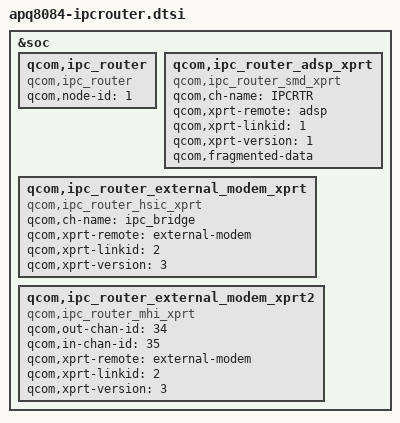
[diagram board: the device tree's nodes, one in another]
/* Copyright (c) 2014-2015, The Linux Foundation. All rights reserved.
 *
 * This program is free software; you can redistribute it and/or modify
 * it under the terms of the GNU General Public License version 2 and
 * only version 2 as published by the Free Software Foundation.
 *
 * This program is distributed in the hope that it will be useful,
 * but WITHOUT ANY WARRANTY; without even the implied warranty of
 * MERCHANTABILITY or FITNESS FOR A PARTICULAR PURPOSE.  See the
 * GNU General Public License for more details.
 */

&soc {
	qcom,ipc_router {
		compatible = "qcom,ipc_router";
		qcom,node-id = <1>;
	};

	qcom,ipc_router_adsp_xprt {
		compatible = "qcom,ipc_router_smd_xprt";
		qcom,ch-name = "IPCRTR";
		qcom,xprt-remote = "adsp";
		qcom,xprt-linkid = <1>;
		qcom,xprt-version = <1>;
		qcom,fragmented-data;
	};

	qcom,ipc_router_external_modem_xprt {
		compatible = "qcom,ipc_router_hsic_xprt";
	        qcom,ch-name = "ipc_bridge";
		qcom,xprt-remote = "external-modem";
		qcom,xprt-linkid = <2>;
		qcom,xprt-version = <3>;
	};

	qcom,ipc_router_external_modem_xprt2 {
		compatible = "qcom,ipc_router_mhi_xprt";
		qcom,out-chan-id = <34>;
		qcom,in-chan-id = <35>;
		qcom,xprt-remote = "external-modem";
		qcom,xprt-linkid = <2>;
		qcom,xprt-version = <3>;
	};
};
